# CALC3_LSE_ICONT register map
Vendor: Texas Instruments
Peripheral module from a debugger description file (folder omap5430_ES2_PUBLIC).
Registers are 32-bit, access per field, reset 0x1 unless marked. A register's access mark holds for its fields unless they carry their own. Offsets are as the file gives them; lines under a group give offsets from that group; [hi:lo] are bit positions; {n}, {i} and the like mark numbered series; 'fields as' and 'values as' point back to an identical list; <NAME> marks a mode.

## CALC3_LSE_ICONT
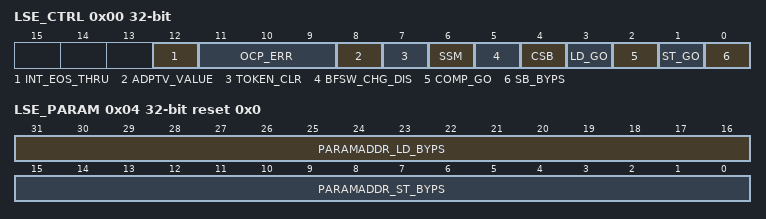
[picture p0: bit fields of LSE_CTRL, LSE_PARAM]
0x00 LSE_CTRL — Controller
  [12] INT_EOS_THRU rw — int_eos through bit 0: LSE does the process for slice boundary after receiving int_eos. 1: int_eos is passed through to SYNCBOX without the process for slice boundary
  [11:9] OCP_ERR rw — OCP error status bit [11]: OCP DMA IP_CORE side [10]: OCP DMA SL2 side [9]: OCP CFG IP_CORE side 0: When Sresp is not ERR 1: When Sresp is ERR Writing 0 is ignored. These bits will remain 1 until RESET or until host sets to 1.
  [8] ADPTV_VALUE ro — Status Adaptv_add() value This signal is cleared, if TOKEN_CLR = 1.
  [7] TOKEN_CLR wo — LSE internal signals will be initialized to understand prologue (first macroblock) as follows: - token status signal - token start/end signal - DMA pointer Writing 0 is ignored. Writing 1 clears some internal signal. This is a self clearing bit. The host will always read '0'. If this is not used for initialization at prologue, some internal signal is kept. Also, synchronization does not function well.
  [6] SSM rw — Single-step mode 1: Enable single-step mode 0: Normal mode
  [5] BFSW_CHG_DIS rw — Disabled internal BFSW change 0: Enable internal BFSW change (default) Then, LSE controls BFSW after LD task finishes. 1: Disable BFSW change (If host wants to control BFSW with each task step by step with LD_GO, COMP_GO, and ST_GO.)
  [4] CSB rw — Command status bit 0: LSE command is defined 1: LSE command is undefined Writing 0 is ignored This bit will remain 1 until RESET or TOKEN_CLR or until host sets to 1.
  [3] LD_GO rw — Execute LOAD task on bypass mode Target ParamAddr_ld_byps needs to be set before this bit is set. 1: Execute LD task. LSE access to ParamAddr_ld_byps and execute the command for LOAD task. 0: Idle Writing 0 is ignored. This bit is cleared after LD Task finishes.
  [2] COMP_GO rw — Execute Comp task on bypass mode 1: Execute ‘Comp task’. In the single-step mode, LSE access to ParamAddr_ld_byps and execute the command for Comp task. In the normal mode, LSE executes COMP commands followed by LD commands. 0: Idle Writing 0 is ignored. This bit is cleared after Comp Task finished.
  [1] ST_GO rw — Execute Store task on bypass mode. Target ParamAddr_st_byps need to set before this bit is set. 1: Execute Store task. LSE access to ParamAddr_st_byps and execute the command for Store task. 0: Idle Writing 0 is ignored This bit is cleared after ST Task finished.
  [0] SB_BYPS rw — SYNCBOX bypass mode: 1: LSE functions SYNCBOX bypass mode and executes the task of GO_BIT. 0: LSE function normal SYNCBOX mode and waits NewTaskSignal. This value should not change during execution.
0x04 LSE_PARAM rw reset 0x0 — Parameter address for SB bypass mode
  [31:16] PARAMADDR_LD_BYPS — Only used in bypass mode. Address of the first command of LD and COMP sequence (128-bit word unit). This is a 128-bit word address, not a byte address. The conversion from byte address to 128-bit word address should be done by the CPU. If LSE_CTRL SB_BYPS is 1, this value is used. In bypass mode, this address is given by this field, instead of SYNCBOX. This field is also used in single-step mode.
  [15:0] PARAMADDR_ST_BYPS — Only used in the bypass mode. Address of the first command of ST sequence [128-bit word unit]. This is 128-bit word address, not byte address. The conversion from byte address to 128-bit word address should be done by CPU. If LSE_CTRL SB_BYPS is 1, this value is used. In the bypass mode, this address is given via this field, instead via SYNCBOX. This field is also used in single-step mode.
